# K1921VG015 register map
Vendor: NIIET; Series: K1921Vxxx; File version: 1.14
Registers are 32-bit, read-write, reset 0x0 unless marked. A register's access mark holds for its fields unless they carry their own. Offsets are from the block's base; [hi:lo] are bit positions; lines under a group give offsets from that group; {n}, {i} and the like mark numbered series; 'fields as' and 'values as' point back to an identical list.

## FLASH — Mainflash control registers
Base 0x3000D000
0x00 ADDR — Address Register
  [18:0] VAL — Address value for flash operations
{0x4+4i} DATA[{i}] (i=0..3) group
  0x00 DATA
    [31:0] VAL — Data register value for flash operations
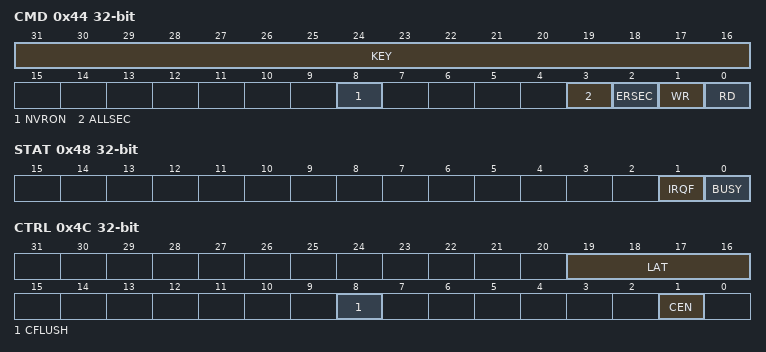
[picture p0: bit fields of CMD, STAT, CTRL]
0x44 CMD — Command Register
  [31:16] KEY — Magic Key for flash access "C0DE"
    0xC0DE=Access (magic Key for flash access)
  [8] NVRON — INFO access bit
  [3] ALLSEC — Enable Erase all flash memory
  [2] ERSEC — Erase sector enable command
  [1] WR — Write enable command
  [0] RD — Read enable command
0x48 STAT — Status Register
  [1] IRQF — IRQ Flag set when command done. Set by hardware only if IRQEN bit is set.
  [0] BUSY ro — Busy status bit when command is processing
0x4C CTRL — Control Register
  [19:16] LAT — Flash latency
  [8] CFLUSH wo — Cache bit
  [1] CEN — Cache enable bit
0xC8 LP — LP mode Register
  [0] LPEN — LowPower mode enable

## SPI0 — SPI control registers
Base 0x20050000
Same registers: SPI1 0x20060000
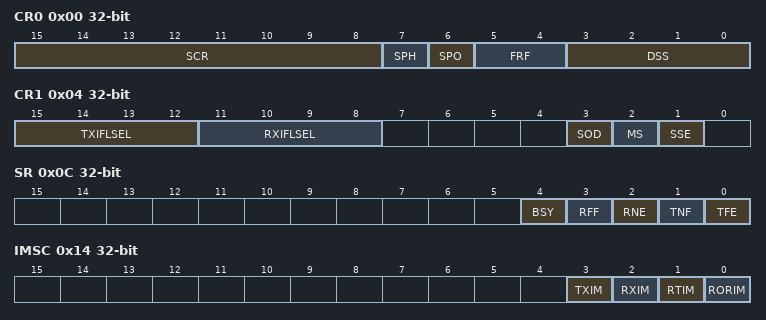
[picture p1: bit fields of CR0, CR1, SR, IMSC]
0x00 CR0 — Control register 0
  [15:8] SCR
  [7] SPH — Phase SSPCLKOUT
  [6] SPO — Polarity SSPCLKOUT
  [5:4] FRF
    0=SPI (SPI of Motorola); 1=SSI (SSI of Texas Instruments); 2=Microwire of National Semiconductor
  [3:0] DSS
    {v}={v+1}bit (data size {v+1} bit) (v=3..15)
0x04 CR1 — Control register 1
  [15:12] TXIFLSEL
  [11:8] RXIFLSEL
  [3] SOD — Disable bit data
  [2] MS — Select mode
  [1] SSE — Enable transceiver
0x08 DR — Data register
  [15:0] DATA
0x0C SR ro — State register
  [4] BSY — Activity flag
  [3] RFF — Indicate full receive buffer
  [2] RNE — Indicate not empty receive buffer
  [1] TNF — Indicator the transmitter FIFO buffer is not full
  [0] TFE — FIFO buffer empty flag transmitter
0x10 CPSR — Clock division factor register
  [7:0] CPSDVSR ro
0x14 IMSC — Mask interrupt register
  [3] TXIM — SSPTXINTR interrupt mask bit to fill 50% or less of the FIFO buffer of the transmitter
  [2] RXIM — SSPRXINTR interrupt mask bit to fill 50% or less of the receiver FIFO buffer
  [1] RTIM — Interrupt mask bit SSPRTINTR timeout receiver
  [0] RORIM — Interrupt mask bit SSPRORINTR buffer overflow receiver
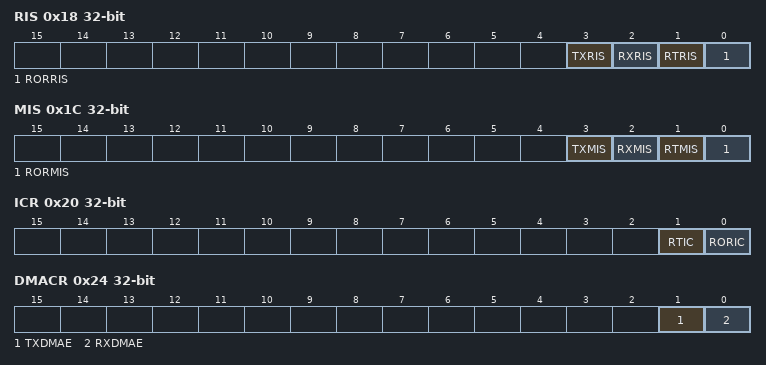
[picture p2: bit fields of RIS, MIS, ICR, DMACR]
0x18 RIS ro — Status register interrupt without mask
  [3] TXRIS — Interrupt status before masking SSPTXINTR
  [2] RXRIS — Interrupt status before masking SSPRXINTR
  [1] RTRIS — Interrupt status before masking SSPRTINTR
  [0] RORRIS — Interrupt status before masking SSPRORINTR
0x1C MIS ro — Status register interrupt masking account
  [3] TXMIS — Masked interrupt status SSPTXINTR
  [2] RXMIS — Masked interrupt status SSPRXINTR
  [1] RTMIS — Masked interrupt status SSPRTINTR
  [0] RORMIS — Masked interrupt status SSPRORINTR
0x20 ICR wo — Register reset interrupt
  [1] RTIC — Reset interrupt SSPRTINTR
  [0] RORIC — Reset interrupt SSPRORINTR
0x24 DMACR — Control register DMA
  [1] TXDMAE — DMA enable bit transmission
  [0] RXDMAE — DMA enable bit at reception

## CAN — CAN controller registers
Base 0x20000000
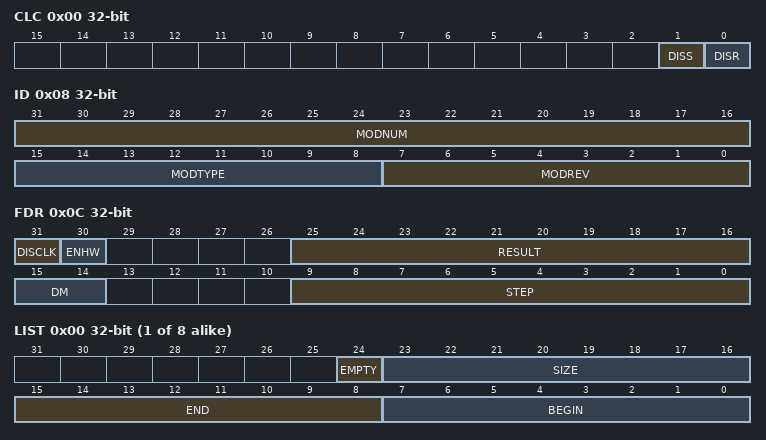
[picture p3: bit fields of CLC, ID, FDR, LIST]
0x00 CLC — Frequency control register
  [1] DISS ro — State CAN
  [0] DISR — OFF module CAN
0x08 ID — Identity register
  [31:16] MODNUM ro, [15:8] MODTYPE ro, [7:0] MODREV
0x0C FDR — Register divider
  [31] DISCLK — Disable bit internal clock
  [30] ENHW — Control bit synchronization
  [25:16] RESULT ro
  [15:14] DM
    0=Disable (counter disabled); 1=NormalMode (normal operation mode); 2=DividerMode (divider operation mode)
  [9:0] STEP
{0x100+4i} LIST[{i}] (i=0..7) group
  0x00 LIST ro — Register list0
    [24] EMPTY — Indicate empty list
    [23:16] SIZE — List size
    [15:8] END
    [7:0] BEGIN
{0x140+4i} MSPND[{i}] (i=0..7) group
  0x00 MSPND — Register waiting interrupts0
    [31:0] PND
{0x180+4i} MSID[{i}] (i=0..7) group
  0x00 MSID ro — Register messages index0
    [5:0] INDEX
0x1C0 MSIMASK — Mask register message index
  [31:0] IM
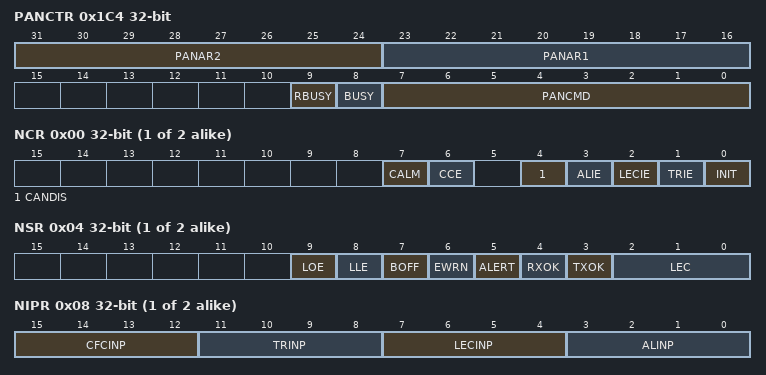
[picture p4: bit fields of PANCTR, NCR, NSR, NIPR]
0x1C4 PANCTR — Register command panel
  [31:24] PANAR2 — Panel argument 9
  [23:16] PANAR1 — Panel argument 8
  [9] RBUSY ro — Busy flag panels arguments (running the command list, the result of which will be recorded in PANAR1 and PANAR2)
  [8] BUSY ro — Busy flag panels arguments (waiting to be written at the end of the command)
  [7:0] PANCMD
0x1C8 MCR — Control register
  [15:12] MPSEL
0x1CC MITR wo — Interrupt register
  [15:0] IT
{0x200+0x100*i} Node[{i}] (i=0..1) group
  0x00 NCR — Register control node0
    [7] CALM — Activate the node analysis
    [6] CCE — Permission node configuration changes
    [4] CANDIS — Off node
    [3] ALIE — Enable interrupt ALERT from node
    [2] LECIE — Interrupt enable bit of the assembly when it detects the last error code
    [1] TRIE — Interrupt enable bit of the assembly at the end of the transmission / reception
    [0] INIT — Node initialization
  0x04 NSR — Register state node0
    [9] LOE — Error Flag Room list
    [8] LLE — Error flag list
    [7] BOFF ro — Status flag 'is disconnected from the bus'
    [6] EWRN ro — Flag critical errors
    [5] ALERT — Warning flag ALERT
    [4] RXOK — Flag successful reception of messages
    [3] TXOK — Flag successful message transmission
    [2:0] LEC
      0=no error; 1=stuff error; 2=form error; 3=AckErr (acknowlegment error); 4=bit 1 error; 5=bit 0 error; 6=CRC error; 7=WriteEn (enable hardware write)
  0x08 NIPR — Interrupt pointer register node0
    [15:12] CFCINP, [11:8] TRINP, [7:4] LECINP, [3:0] ALINP
  0x0C NPCR — Port control register node0
    [8] LBM — Enable mode Loop-Back
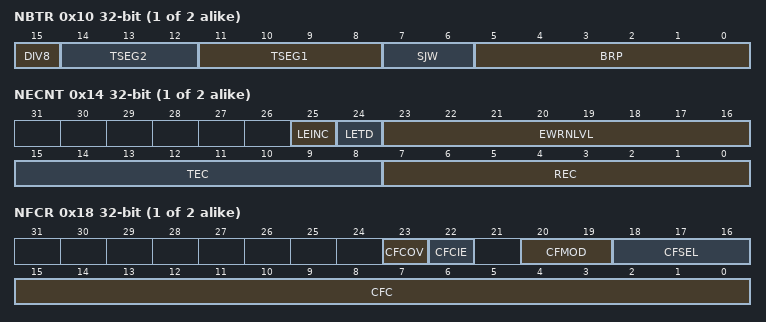
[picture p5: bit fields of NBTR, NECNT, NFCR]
  0x10 NBTR — Timing register bits 0
    [15] DIV8 — Frequency divider by 8
    [14:12] TSEG2
    [11:8] TSEG1
    [7:6] SJW
    [5:0] BRP
  0x14 NECNT — Counter error register node0
    [25] LEINC ro — Indicator increment at the last error
    [24] LETD ro — Flag last transmission errors
    [23:16] EWRNLVL
    [15:8] TEC
    [7:0] REC
  0x18 NFCR — Register message counter node0
    [23] CFCOV — Counter overflow flag messages
    [22] CFCIE — Interrupt enable bit of the message counter
    [20:19] CFMOD
    [18:16] CFSEL
    [15:0] CFC

## CANMSG — CAN Msg registers
Base 0x20001000
{0x0+0x20*i} Msg[{i}] (i=0..127) group
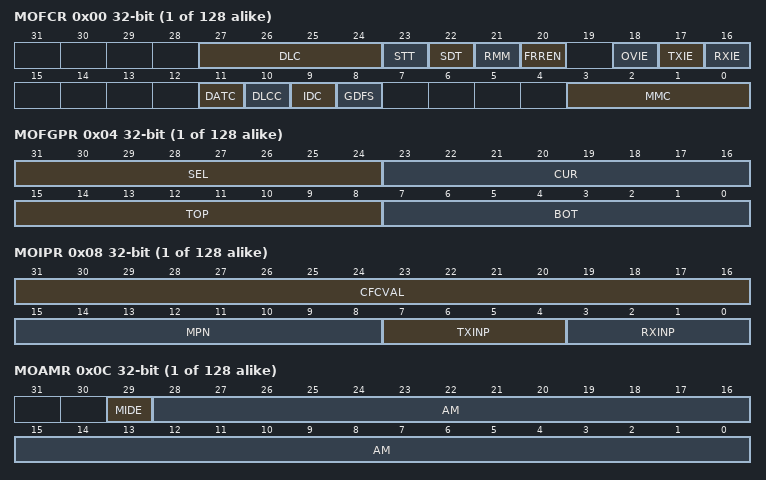
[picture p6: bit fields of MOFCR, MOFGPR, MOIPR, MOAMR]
  0x00 MOFCR — Register control the operation of the message object 0
    [27:24] DLC
    [23] STT — Bit single data transfer
    [22] SDT — Bit single of the message object 0 participation in shipment
    [21] RMM — Enable remote monitoring of the communication object
    [20] FRREN — Enable remote request
    [18] OVIE — Interrupt enable FIFO to fill the message object 0
    [17] TXIE — Interrupt enable at the end of the message
    [16] RXIE — Interrupt enable after taking the messages
    [11] DATC
    [10] DLCC
    [9] IDC
    [8] GDFS
    [3:0] MMC
      0=MsgObj (message object); 1=RXObj (receiver FIFO structure object); 2=TXObj (transmitter FIFO structure object); 3=SlaveTXObj (transmitter FIFO structure slave object); 4=SrcObj (gateway source object)
  0x04 MOFGPR — Pointer register FIFO / gateway message object 0
    [31:24] SEL, [23:16] CUR, [15:8] TOP, [7:0] BOT
  0x08 MOIPR — Pointer register interrupt message object 0
    [31:16] CFCVAL, [15:8] MPN, [7:4] TXINP, [3:0] RXINP
  0x0C MOAMR — Mask register message object 0
    [29] MIDE — Mask bit IDE message
    [28:0] AM
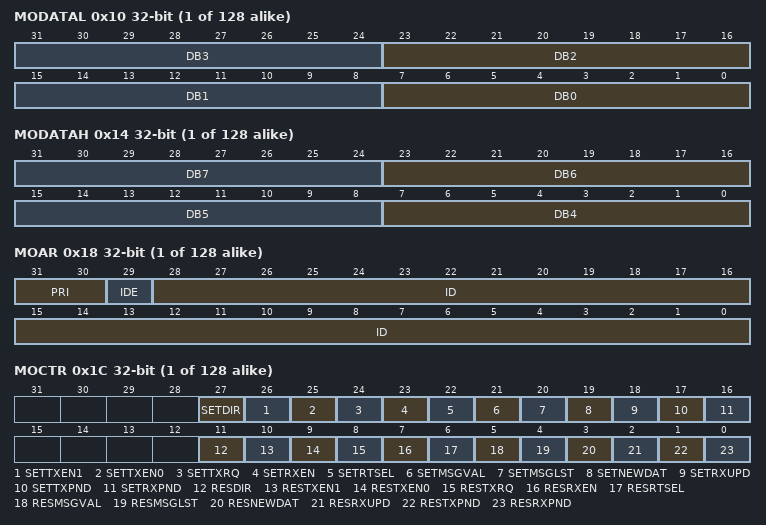
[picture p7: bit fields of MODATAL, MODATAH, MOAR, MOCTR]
  0x10 MODATAL — Low data registers of the message object 0
    [8n+7:8n] DB{n} (n=0..3)
  0x14 MODATAH — High data registers of the message object 0
    [8n-25:8n-32] DB{n} (n=4..7)
  0x18 MOAR — Register arbitration message object 0
    [31:30] PRI
    [29] IDE — Bit extension identifier of the message object 0
    [28:0] ID
  0x1C MOCTR wo — Control register Message object 0
    [27] SETDIR — Set bit DIR
    [26] SETTXEN1 — Set bit TXEN1
    [25] SETTXEN0 — Set bit TXEN0
    [24] SETTXRQ — Set bit TXRQ
    [23] SETRXEN — Set bit RXEN
    [22] SETRTSEL — Set bit RTSEL
    [21] SETMSGVAL — Set bit MSGVAL
    [20] SETMSGLST — Set bit MSGLST
    [19] SETNEWDAT — Set bit NEWDAT
    [18] SETRXUPD — Set bit RXUPD
    [17] SETTXPND — Set bit TXPND
    [16] SETRXPND — Set bit RXPND
    [11] RESDIR — Reset bit DIR
    [10] RESTXEN1 — Reset bit TXEN1
    [9] RESTXEN0 — Reset bit TXEN0
    [8] RESTXRQ — Reset bit TXRQ
    [7] RESRXEN — Reset bit RXEN
    [6] RESRTSEL — Reset bit RTSEL
    [5] RESMSGVAL — Reset bit MSGVAL
    [4] RESMSGLST — Reset bit MSGLST
    [3] RESNEWDAT — Reset bit NEWDAT
    [2] RESRXUPD — Reset bit RXUPD
    [1] RESTXPND — Reset bit TXPND
    [0] RESRXPND — Reset bit RXPND
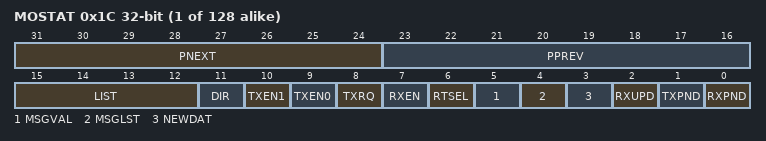
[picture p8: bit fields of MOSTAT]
  0x1C MOSTAT ro (alternate view of MOFCR) — Status register of the message object 0
    [31:24] PNEXT
    [23:16] PPREV
    [15:12] LIST
    [11] DIR — Bit allocation
    [10] TXEN1 — Enable bit transmission frame
    [9] TXEN0 — Enable bit transmission frame
    [8] TXRQ — Initiate transmission
    [7] RXEN — Bits allow reception
    [6] RTSEL — The indication of transmission / reception
    [5] MSGVAL — Activity bit of the message object 0
    [4] MSGLST — Bit message loss
    [3] NEWDAT — New data indicator
    [2] RXUPD — Indicator changes
    [1] TXPND — Indicator end of transmission
    [0] RXPND — Indicator deadline

## CMP — CMP controller registers
Base 0x38010000
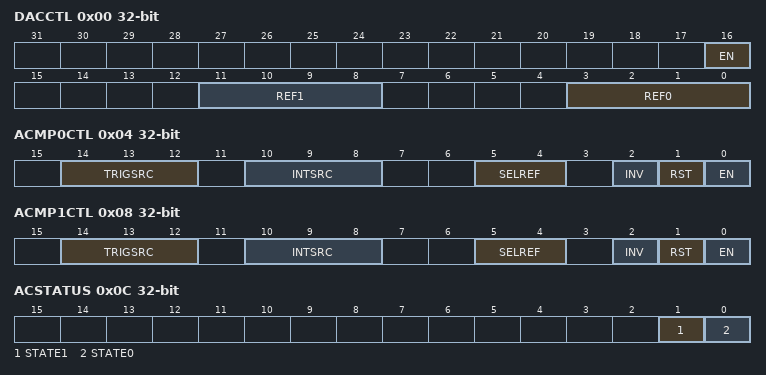
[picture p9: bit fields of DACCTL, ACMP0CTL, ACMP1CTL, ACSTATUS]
0x00 DACCTL — DAC control register
  [16] EN, [11:8] REF1, [3:0] REF0
0x04 ACMP0CTL — ACMP0 control register
  [14:12] TRIGSRC, [10:8] INTSRC, [5:4] SELREF, [2] INV, [1] RST, [0] EN
0x08 ACMP1CTL — ACMP1 control register
  fields as ACMP0CTL
0x0C ACSTATUS ro — ACMP status
  [1] STATE1, [0] STATE0
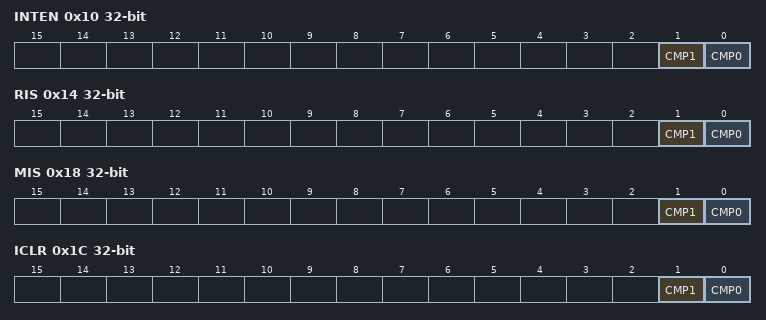
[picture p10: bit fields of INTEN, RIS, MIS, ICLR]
0x10 INTEN — Interrupt enable
  [1] CMP1, [0] CMP0
0x14 RIS ro — Raw interrupt status
  [1] CMP1, [0] CMP0
0x18 MIS ro — Masked interrupt status
  [1] CMP1, [0] CMP0
0x1C ICLR wo — Clear interrupt status
  [1] CMP1, [0] CMP0
